# tviic2d6mddr register map
Vendor: Cypress Semiconductor; Series: tviic2d6mddr; File version: 1.0
CPU: CM7 r0p1, little endian, MPU, FPU, VTOR, 3 interrupt priority bits
Registers are 32-bit, read-write, reset 0x0 unless marked. A register's access mark holds for its fields unless they carry their own. Offsets are from the block's base; [hi:lo] are bit positions; lines under a group give offsets from that group; {n}, {i} and the like mark numbered series; 'fields as' and 'values as' point back to an identical list.

## VIDEOSS0 (part 4 of 18) — Video and Graphics Subsystem IP
Base 0x40A00000
0x80000 VIDEOIO group — Video I/O Core
  0x00 SUBIO group — Sub Interface
    0x00 VIDEOIOCFG group — Video I/O Core Configuration
      0x00 INTR_VIDEOIO0 — Interrupt status register 0
        [23:0] INTR_VIDEOIO0 — Interrupt status vector. A bit is set when the related event occurs or the corresponding bit of INTR_VIDEOIO0_SET is written. By writing 1 the corresponding bit is cleared. Bit 0 = ExtDst0_ShdLoad Bit 1 = ExtDst0_FrameComplete Bit 2 = ExtDst0_SeqComplete Bit 3 = ExtDst4_ShdLoad Bit 4 = ExtDst4_FrameComplete Bit 5 = ExtDst4_SeqComplete Bit 6 = ExtDst1_ShdLoad Bit 7 = ExtDst1_FrameComplete Bit 8 = ExtDst1_SeqComplete Bit 9 = ExtDst5_ShdLoad Bit 10 = ExtDst5_FrameComplete Bit 11 = ExtDst5_SeqComplete Bit 12 = Store4_ShdLoad Bit 13 = Store4_FrameComplete Bit 14 = Store4_SeqComplete Bit 15 = Histogram4_Valid Bit 16 = FrameDump_Error Bit 17 = FrameCap0_Sync_On Bit 18 = FrameCap0_Sync_Off Bit 19 = ItuIfc0_Error Bit 20 = GeneralPurpose0 Bit 21 = GeneralPurpose1 Bit 22 = GeneralPurpose2 Bit 23 = GeneralPurpose3
      0x04 INTR_VIDEOIO1 — Interrupt Status register 1
      0x08 INTR_VIDEOIO0_SET wo reset not defined — Interrupt set register 0
        [23:0] INTR_VIDEOIO0_SET — Interrupt set vector. Writing a 1 to this fields sets status in INTR_VIDEOIO0.
      0x0C INTR_VIDEOIO1_SET wo reset not defined — Interrupt set register 1
        [31:0] INTR_VIDEOIO1_SET — Interrupt set vector. Writing a 1 to this fields sets status in INTR_VIDEOIO1.
      0x10 INTR_VIDEOIO0_MASK — Interrupt mask register 0
        [23:0] INTR_VIDEOIO0_MASK — Interrupt mask vector. When a bit is set in this field, the related INTR_VIDEOIO0 status activates the interrupt signal.
      0x14 INTR_VIDEOIO1_MASK — Interrupt mask register 1
        [31:0] INTR_VIDEOIO1_MASK — Interrupt mask vector. When a bit is set in this field, the related INTR_VIDEOIO1 status activates the interrupt signal.
      0x18 INTR_VIDEOIO0_MASKED ro reset not defined — Interrupt masked register 0
        [23:0] INTR_VIDEOIO0_MASKED — Status vector INTR_VIDEOIO0 masked with INTR_VIDEOIO0_MASK.
      0x1C INTR_VIDEOIO1_MASKED ro reset not defined — Interrupt masked register 1
        [31:0] INTR_VIDEOIO1_MASKED — Status vector INTR_VIDEOIO1 masked with INTR_VIDEOIO1_MASK.
      0x20 INTR_VIDEOIO0_SAFETY — Interrupt Status register 0
        [23:0] INTR_VIDEOIO0_SAFETY — Interrupt status vector. A bit is set when the related event occurs or the corresponding bit of INTR_VIDEOIO0_SET is written. By writing 1 the corresponding bit is cleared. Bit mapping is same like in INTR_VIDEOIO0.
      0x24 INTR_VIDEOIO1_SAFETY — Interrupt Status register 1
        [31:0] INTR_VIDEOIO1_SAFETY — Interrupt status vector. A bit is set when the related event occurs or the corresponding bit of INTR_VIDEOIO0_SET is written. By writing 1 the corresponding bit is cleared. Bit mapping is same like in INTR_VIDEOIO1.
      0x28 INTR_VIDEOIO0_SAFETY_SET wo reset not defined — Interrupt set register 0
        [23:0] INTR_VIDEOIO0_SAFETY_SET — Interrupt set vector. Writing a 1 to this fields sets status in INTR_VIDEOIO0_SAFETY.
      0x2C INTR_VIDEOIO1_SAFETY_SET wo reset not defined — Interrupt set register 1
        [31:0] INTR_VIDEOIO1_SAFETY_SET — Interrupt set vector. Writing a 1 to this fields sets status in INTR_VIDEOIO1_SAFETY.
      0x30 INTR_VIDEOIO0_SAFETY_MASK — Interrupt mask register 0
        [23:0] INTR_VIDEOIO0_SAFETY_MASK — Interrupt mask vector. When a bit is set in this field, the related INTR_VIDEOIO0_SAFETY status activates the interrupt_safety signal.
      0x34 INTR_VIDEOIO1_SAFETY_MASK — Interrupt mask register 1
        [31:0] INTR_VIDEOIO1_SAFETY_MASK — Interrupt mask vector. When a bit is set in this field, the related INTR_VIDEOIO1_SAFETY status activates the interrupt_safety signal.
      0x38 INTR_VIDEOIO0_SAFETY_MASKED ro reset not defined — Interrupt masked register 0
        [23:0] INTR_VIDEOIO0_SAFETY_MASKED — Status vector INTR_VIDEOIO0_SAFETY masked with INTR_MASK_SAFETY0.
      0x3C INTR_VIDEOIO1_SAFETY_MASKED ro reset not defined — Interrupt masked register 1
        [31:0] INTR_VIDEOIO1_SAFETY_MASKED — Status vector INTR_VIDEOIO1_SAFETY masked with INTR_MASK_SAFETY1.
    0x400 FRAMEDUMP group — Frame Dump Unit
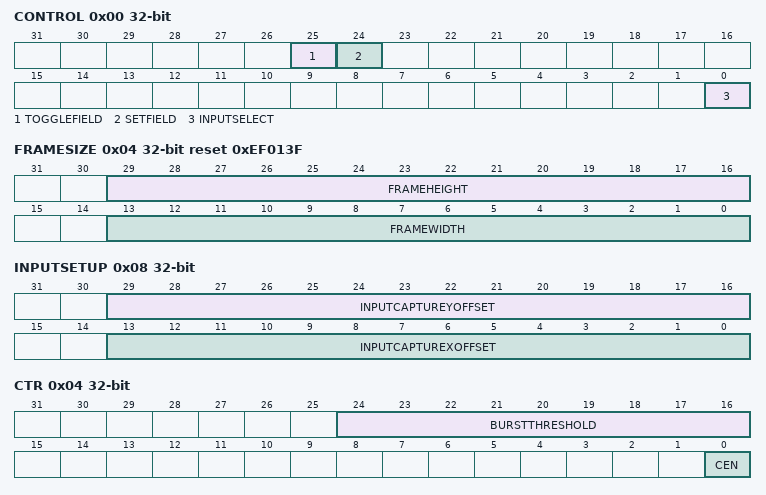
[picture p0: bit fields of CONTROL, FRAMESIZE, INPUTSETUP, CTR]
      0x00 CONTROL — Control settings.
        [25] TOGGLEFIELD — Enable toggling of the field property from frame to frame. Set to '1' to enable.
        [24] SETFIELD — The field property of the generated frame is set to this value. If field toggle is used, this is the start value.
        [0] INPUTSELECT — Index of display stream that is dumped.
      0x04 FRAMESIZE reset 0xEF013F — Dump window size.
        [29:16] FRAMEHEIGHT — Height of output frame of framedump, given minus one. Do not change during operation.
        [13:0] FRAMEWIDTH — Width of output frame of framedump, given minus one. Do not change during operation.
      0x08 INPUTSETUP — Dump window position.
        [29:16] INPUTCAPTUREYOFFSET — Y offset of capture area. Note that capture windows must not overlap the last row of the input frame. Do not change during operation.
        [13:0] INPUTCAPTUREXOFFSET — X offset of capture area. Note that capture windows must not overlap the last column of the input frame. Do not change during operation.
      0x0C ENABLE
        [0] DUMPEN — If this is set to 1, the framedump unit will continuously dump all input frames. If set to 0, DumpReq is the other option of triggering the dumping of an input frame.
      0x10 TRIGGER — Trigger bits.
        [0] DUMPREQ — Next frame is dumped when this field is set. It is reset by HW once dumping of frame data has started. It cannot be reset by SW.
      0x14 STATUS ro reset 0x1
        [0] DUMPIDLE — If read as '1', the framedump unit is currently not dumping any frames. If read as '0' the framedump unit is currently dumping frames.
    0x1000 CAPENG0 group — Capture Engine
      0x400 FRAMECAP group — Frame Capture Unit
        0x00 CAPTUREMODE — Capture mode configuration. FrameCap input mode configuration.
          [1:0] CAPTUREMODE — Selects a capture mode. Do not change during operation of FrameCap unit.
            0=ENHSVS_32BIT (Capture of 32-bit parallel or MIPI_CSI2 pixel input data with dedicated frame synchronization signals); 1=ITU656_10BIT (Capture of ITU656 10 bit data); 2=ITU656_8BIT (Capture of ITU656 8 bit data)
        0x04 CTR — FrameCap control register for starting the unit
          [24:16] BURSTTHRESHOLD — When setting a burst threshold larger 0, the generation of output pixels is initially locked. It is unlocked once the number of pixels captured into an internal FIFO is larger than the programmed value or when the last active pixel of an input frame has been received. Once unlocked it is locked again when the FIFO runs empty. This function can have a positive effect on memory access efficiency, depending on the system's Video RAM type.
          [0] CEN — CaptureEnable=1, enable bit for FrameCap unit. Capture starts with next frame sync signal. CaptureEnable=0, disable bit for FrameCap unit. Current frame is completed before FrameCap is stopped.
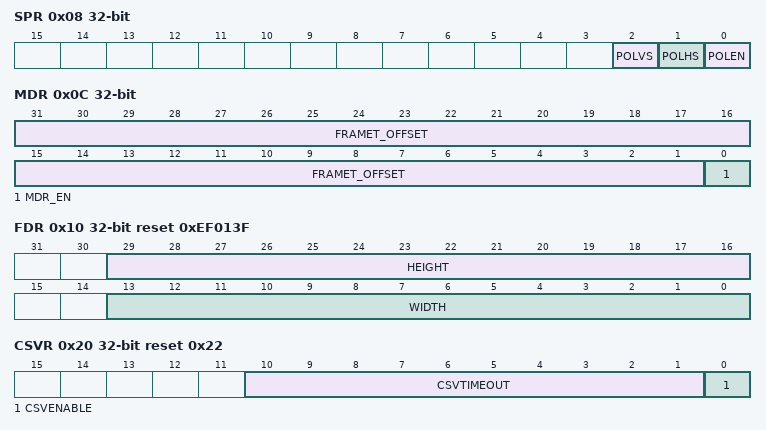
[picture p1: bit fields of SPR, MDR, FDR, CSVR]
        0x08 SPR — FrameCap sync signal polarity configuration.
          [2] POLVS — Change polarity of video signal vsync.
            0=LOWACT (Signal is active low (default).); 1=HIGHACT (Signal is active high.)
          [1] POLHS — Change polarity of video signal hsync.
            values as POLVS
          [0] POLEN — Change polarity of video signal de.
            0=HIGHACT (Signal is active high (default).); 1=LOWACT (Signal is active low.)
        0x0C MDR — FrameCap control register for starting the mode detection
          [31:1] FRAMET_OFFSET — Frame size tolerance which will not generate a mode detection size mismatch. Set an offset for frame time duration.
          [0] MDR_EN — Mdr_en=1, enable bit for FrameCap mode detection and pixel frame rate measurement for the captured frame. Make sure that MdSts0.MdrCmrDone is 1 before starting it again. Mdr_en=0, disable bit for FrameCap mode detection.
        0x10 FDR reset 0xEF013F — Frame dimension (progressive frame and field 0).
          [29:16] HEIGHT — Expected frame height of video frames and fields with id 0 (value is Height - 1). It could be configured after mode detection.
          [13:0] WIDTH — Expected frame width of video frame (value is Width - 1). It could be configured after mode detection.
        0x14 FDR1 reset 0xEF0000 — Frame dimension (field 1).
          [29:16] HEIGHT1 — Expected frame height of video fields with id 1 (value is Height - 1). It could be configured after mode detection.
        0x18 KDR — FrameCap kick delay configuration register
          [27:0] KICKDEL — Delay after receiving last active pixel in frame (in video clock cycles) until the kick pulse is generated. In any case the kick pulse is generated with first active pixel of next frame latest.
        0x1C SCR reset 0x2 — FrameCap Sync frame number configuration register
          [3:0] FUS — Number of consecutive frames captured until synchronization state is reached (value of 0 is not allowed). indicated by sts signal and register field Sts.SyncStat.
        0x20 CSVR reset 0x22 — Framecap control register for capture clock supervision
          [10:1] CSVTIMEOUT — setting a time limitation for waiting the recovery of capture clock. The value should be bigger than 11 or equal to 11, otherwise it reports fake clk_cap loss.
          [0] CSVENABLE — CsvEnable=1, start a capture clock supervision.
        0x24 STSCLR wo reset not defined — FrameCap status clear register. Clears the status bits of Sts register, Mdr_SizeChange and Csv_lost field.
          [0] STATUSCLEAR — Clears status bits of Sts register.
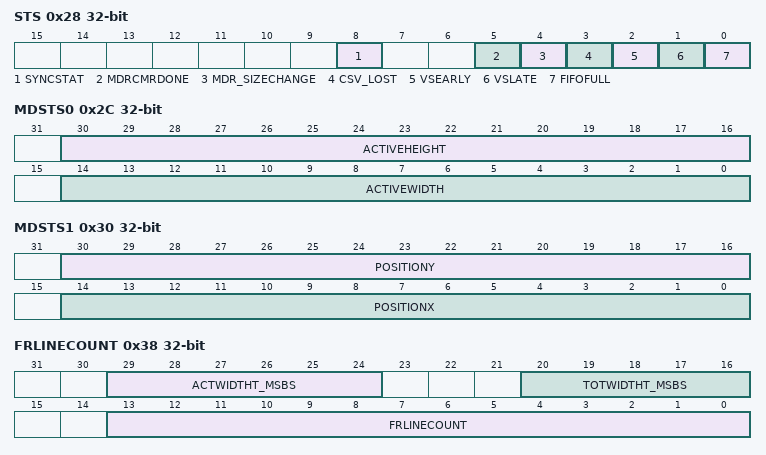
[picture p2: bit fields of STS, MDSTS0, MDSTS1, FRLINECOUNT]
        0x28 STS ro — FrameCap status register. Current status of the FrameCap module.
          [8] SYNCSTAT — Indicates the current state of synchronization (0 = out of sync, 1 = in sync). Note: A loss of the video stream cannot be detected using this field. Use the framegen status fields for this purpose.
          [5] MDRCMRDONE — MdrCmrDone=1 means that the mode detection is completed and pixel clock measurement is done. (bit locked when 1, clear by writing StatusClear field).
          [4] MDR_SIZECHANGE — Mdr_SizeChange=1, frame size of the video frame detected is not consistent. (bit locked when 1, clear by writing StatusClear field). If frame size change, the clock measurement fails.
          [3] CSV_LOST — Csv_Lost=1, capture clock is not available. Csv_Lost=0, capture clock is resumed.(bit locked when 1, cleared by writing StatusClear field).
          [2] VSEARLY — VSYNC is detected too early. The received frame is too small (bit locked when 1, cleared by writing StatusClear field).
          [1] VSLATE — VSYNC is detected too late. The received frame is too big (bit locked when 1, cleared by writing StatusClear field).
          [0] FIFOFULL — Write Access to the full coupling FIFO (bit locked when 1, cleared by writing StatusClear field).
        0x2C MDSTS0 ro — FrameCap mode detection status register for the active part of the video frames.(bit locked when MdrCmrDone=1).
          [30:16] ACTIVEHEIGHT — Frame height of active part of the video frame detected by the mode detection. The status can be read when MdrCmrDone=1.
          [14:0] ACTIVEWIDTH — Frame width of active part of the video frame detected by the mode detection. The status can be read when MdrCmrDone=1.
        0x30 MDSTS1 ro — FrameCap mode detection status register. The current (x,y) position of the capture stream (with respect to the output).
          [30:16] POSITIONY — the current Y position of the capture stream.
          [14:0] POSITIONX — the current X position of the capture stream.
        0x34 FRCNT ro — FrameCap frame counter register indicating the corresponding clk_axi cycles.
          [31:0] FRCOUNT — Shows frame counts of video input. It is updated every vsync (for debugging purposes only).
        0x38 FRLINECOUNT ro (reset mask 0x3F1F0000) — FrameCap line counter register.
          [29:24] ACTWIDTHT_MSBS — MSBs of CmSts1.ActWidthT. Bit locked when MdrCmrDone=1.
          [20:16] TOTWIDTHT_MSBS — MSBs of CmSts1.TotWidthT. Bit locked when MdrCmrDone=1.
          [13:0] FRLINECOUNT — Shows current line number of input timing. Incremented with leading edge of hsync signal, set to 0 with leading edge of vsync signal.
        0x3C CMSTS1 ro — clk_axi cycle number of a frame. (bit locked when MdrCmrDone=1).
          [29:0] TOTAL_TIME — clk_axi cycle number of a frame starting from vsync to another vsync.
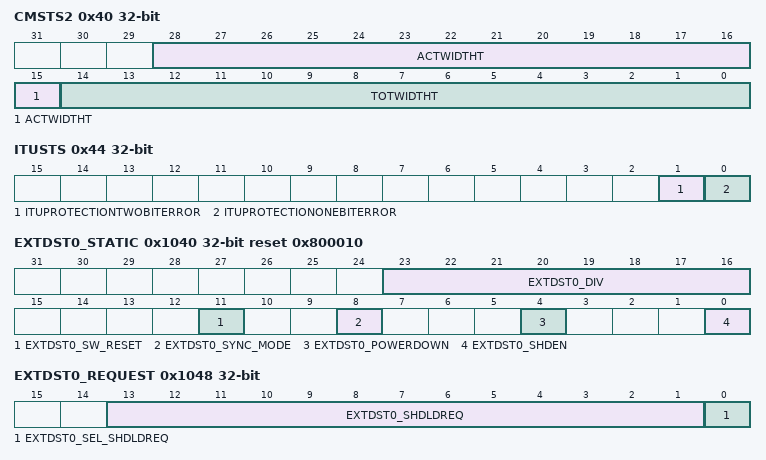
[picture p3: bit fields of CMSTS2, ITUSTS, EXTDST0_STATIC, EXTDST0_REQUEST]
        0x40 CMSTS2 ro — clk_axi cycle number of totwidth and actwidth of a frame. (bit locked when MdrCmrDone=1).
          [28:15] ACTWIDTHT — cycle number of the active part of a video frame line for calculating pixel frame rate. LSBs contained in this field, MSBs contained in FRLineCount.ActWidthT_MSBs.
          [14:0] TOTWIDTHT — cycle number of the total part of a video frame line for calculating pixel frame rate. LSBs contained in this field, MSBs contained in FRLineCount.TotWidthT_MSBs.
        0x44 ITUSTS — ITU error status register.
          [1] ITUPROTECTIONTWOBITERROR — Set if a two bit error in the reference code of the ITU capture input 0 is found. Two bit errors can only be detected, not corrected. Clear by writing a 1 to this field.
          [0] ITUPROTECTIONONEBITERROR — Set if a one bit error in the reference code of the ITU capture input 0 is found and corrected. Clear by writing a 1 to this field.
    0x10000 COMPENG group — Composition Engine
      0x00 COMPENGCFG group — Top-Level
        {0x0+4m} PALETTE[{m}] (m=0..1023) reset not defined — Shared Color Palette Memory.
          [23:0] PALETTEENTRY — Shared palette entry with 24-bit. Color format can be defined by Fetch configuration.
        0x1000 EXTDST0_SAFETYMASK reset 0x1FFFFF — Safety mask for extdst0
          [20:0] EXTDST0_SAFETYMASK — Each bit in this field describes whether the corresponding processing unit is allowed to be configured in a path leading to this endpoint (extdst0). 1 = allowed, 0 = prohibited.
        0x1004 EXTDST4_SAFETYMASK reset 0x1FFFFF — Safety mask for extdst4
          [20:0] EXTDST4_SAFETYMASK — Each bit in this field describes whether the corresponding processing unit is allowed to be configured in a path leading to this endpoint (extdst4). 1 = allowed, 0 = prohibited.
        0x1008 EXTDST1_SAFETYMASK reset 0x1FFFFF — Safety mask for extdst1
          [20:0] EXTDST1_SAFETYMASK — Each bit in this field describes whether the corresponding processing unit is allowed to be configured in a path leading to this endpoint (extdst1). 1 = allowed, 0 = prohibited.
        0x100C EXTDST5_SAFETYMASK reset 0x1FFFFF — Safety mask for extdst5
          [20:0] EXTDST5_SAFETYMASK — Each bit in this field describes whether the corresponding processing unit is allowed to be configured in a path leading to this endpoint (extdst5). 1 = allowed, 0 = prohibited.
        0x1010 STORE4_SAFETYMASK reset 0x1FFFFF — Safety mask for store4
          [20:0] STORE4_SAFETYMASK — Each bit in this field describes whether the corresponding processing unit is allowed to be configured in a path leading to this endpoint (store4). 1 = allowed, 0 = prohibited.
        0x1020 CONSTFRAME0_STATUS ro reset not defined — Status information for pixel engine configuration of constframe0
          [18:16] CONSTFRAME0_SEL — Status of the connection of the constframe0 module
            1=EXTDST0 (constframe0 module is used from extdst0 processing path); 2=EXTDST4 (constframe0 module is used from extdst4 processing path); 3=EXTDST1 (constframe0 module is used from extdst1 processing path); 4=EXTDST5 (constframe0 module is used from extdst5 processing path); 5=STORE4 (constframe0 module is used from store4 processing path); 0=DISABLE (constframe0 module is not used)
        0x1040 EXTDST0_STATIC reset 0x800010 — Static pixel engine configuration for extdst0
          [23:16] EXTDST0_DIV
          [11] EXTDST0_SW_RESET — Software reset for extdst0 synchronizer, for debug purposes only
            0=OPERATION (Normal Operation); 1=SWRESET (Software Reset)
          [8] EXTDST0_SYNC_MODE — Synchronization mode for extdst0 pipeline endpoint synchronizer
            0=SINGLE (Reconfig pipeline after explicit trigger); 1=AUTO (Reconfig pipeline after every kick when idle)
          [4] EXTDST0_POWERDOWN — Set this to 1 to activate powerdown or to 0 to deactivate powerdown for the extdst0 endpoint.
          [0] EXTDST0_SHDEN — Enables shadowing of all RWS type registers (0=write_through, 1=shadowed) for pixelbus configuration of pipeline with endpoint extdst0.
        0x1044 EXTDST0_DYNAMIC reset 0x17 — Dynamic pixel engine configuration for extdst0
          [4:0] EXTDST0_SRC_SEL — Selection of the source for the src input of the extdst0 module
            0=DISABLE (Unit extdst0 input port src is disabled); 1=CONSTFRAME0 (Unit extdst0 input port src is connected to output of unit constframe0); 20=GPSCALER4 (Unit extdst0 input port src is connected to output of unit gpscaler4); 9=EXTSRC4 (Unit extdst0 input port src is connected to output of unit extsrc4); {v}=LAYERBLEND{v-21} (Unit extdst0 input port src is connected to output of unit layerblend{v-21}) (v=22..26)
        0x1048 EXTDST0_REQUEST — ShadowLoadRequest register for endpoint extdst0
          [13:1] EXTDST0_SHDLDREQ — Vector of shadow load request flag of all sources for destination extdst0. Setting a bit has no effect if the source is currently in a different pipeline than the one of destination extdst0.
          [0] EXTDST0_SEL_SHDLDREQ — Shadow load request flag for destination extdst0.
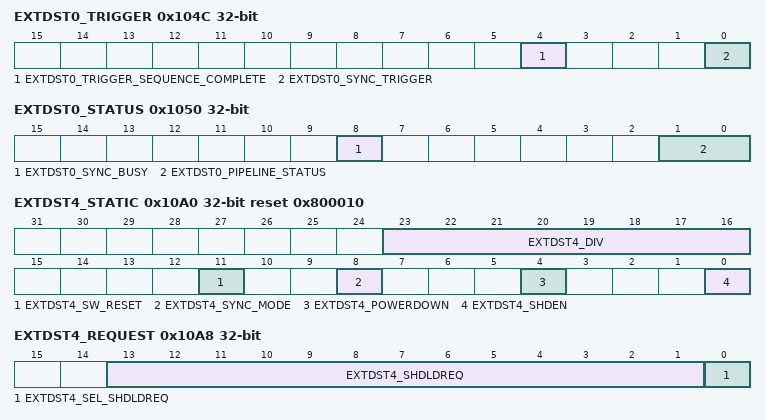
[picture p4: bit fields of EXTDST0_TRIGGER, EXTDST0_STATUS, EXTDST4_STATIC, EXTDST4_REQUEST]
        0x104C EXTDST0_TRIGGER wo reset not defined — Trigger bits for pixel engine configuration of extdst0
          [4] EXTDST0_TRIGGER_SEQUENCE_COMPLETE — By writing a '1' to this register field, you can trigger the extdst0 sequence complete interrupt that will occur as soon as the pipeline with the endpoint extdst0 is empty. This interrupt will also occur if the pipeline is already empty when this field is written. The interrupt will not occur if this field is not written. The interrupt will occur exactly as often as this field is written, assuming that this field is not written again until the interrupt has occured after a previous trigger.
          [0] EXTDST0_SYNC_TRIGGER — Writing a '1' to this field triggers reconfiguration of the pipeline with endpoint extdst0
        0x1050 EXTDST0_STATUS ro — Status information for pixel engine configuration of extdst0
          [8] EXTDST0_SYNC_BUSY — Synchronization busy status of extdst0 endpoint
            0=IDLE (extdst0 synchronizer is idle); 1=BUSY (extdst0 synchronizer is busy)
          [1:0] EXTDST0_PIPELINE_STATUS — Status of pipeline with endpoint extdst0
            0=EMPTY (Pipeline with endpoint extdst0 is empty); 1=RUNNING (Pipeline with endpoint extdst0 is currently processing one operation); 2=RUNNING_RETRIGGERED (Pipeline with endpoint extdst0 is currently processing one operation with a second one already kicked to be processed afterwards); 3=RSVD (N/A)
        0x1080 CONSTFRAME4_STATUS ro reset not defined — Status information for pixel engine configuration of constframe4
          [18:16] CONSTFRAME4_SEL — Status of the connection of the constframe4 module
            1=EXTDST0 (constframe4 module is used from extdst0 processing path); 2=EXTDST4 (constframe4 module is used from extdst4 processing path); 3=EXTDST1 (constframe4 module is used from extdst1 processing path); 4=EXTDST5 (constframe4 module is used from extdst5 processing path); 5=STORE4 (constframe4 module is used from store4 processing path); 0=DISABLE (constframe4 module is not used)
        0x10A0 EXTDST4_STATIC reset 0x800010 — Static pixel engine configuration for extdst4
          [23:16] EXTDST4_DIV
          [11] EXTDST4_SW_RESET — Software reset for extdst4 synchronizer, for debug purposes only
            0=OPERATION (Normal Operation); 1=SWRESET (Software Reset)
          [8] EXTDST4_SYNC_MODE — Synchronization mode for extdst4 pipeline endpoint synchronizer
            values as VIDEOIO.SUBIO.COMPENG.COMPENGCFG.EXTDST0_STATIC.EXTDST0_SYNC_MODE
          [4] EXTDST4_POWERDOWN — Set this to 1 to activate powerdown or to 0 to deactivate powerdown for the extdst4 endpoint.
          [0] EXTDST4_SHDEN — Enables shadowing of all RWS type registers (0=write_through, 1=shadowed) for pixelbus configuration of pipeline with endpoint extdst4.
        0x10A4 EXTDST4_DYNAMIC — Dynamic pixel engine configuration for extdst4
          [4:0] EXTDST4_SRC_SEL — Selection of the source for the src input of the extdst4 module
            0=DISABLE (Unit extdst4 input port src is disabled); 3=CONSTFRAME4 (Unit extdst4 input port src is connected to output of unit constframe4); 20=GPSCALER4 (Unit extdst4 input port src is connected to output of unit gpscaler4); 9=EXTSRC4 (Unit extdst4 input port src is connected to output of unit extsrc4); {v}=LAYERBLEND{v-21} (Unit extdst4 input port src is connected to output of unit layerblend{v-21}) (v=22..26)
        0x10A8 EXTDST4_REQUEST — ShadowLoadRequest register for endpoint extdst4
          [13:1] EXTDST4_SHDLDREQ — Vector of shadow load request flag of all sources for destination extdst4. Setting a bit has no effect if the source is currently in a different pipeline than the one of destination extdst4.
          [0] EXTDST4_SEL_SHDLDREQ — Shadow load request flag for destination extdst4.
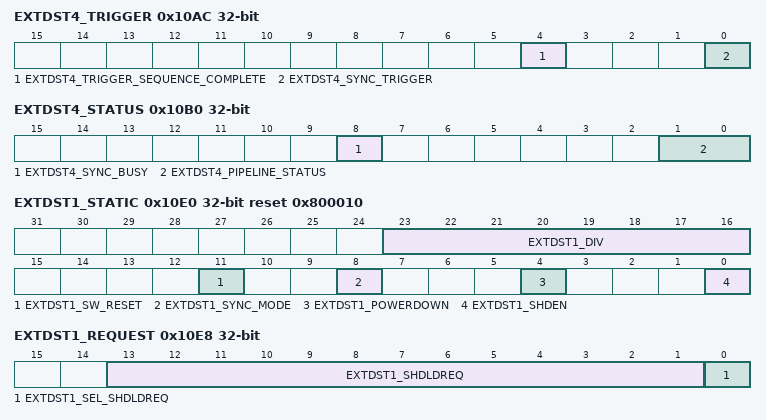
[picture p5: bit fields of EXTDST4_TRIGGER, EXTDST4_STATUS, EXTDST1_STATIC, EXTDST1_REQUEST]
        0x10AC EXTDST4_TRIGGER wo reset not defined — Trigger bits for pixel engine configuration of extdst4
          [4] EXTDST4_TRIGGER_SEQUENCE_COMPLETE — By writing a '1' to this register field, you can trigger the extdst4 sequence complete interrupt that will occur as soon as the pipeline with the endpoint extdst4 is empty. This interrupt will also occur if the pipeline is already empty when this field is written. The interrupt will not occur if this field is not written. The interrupt will occur exactly as often as this field is written, assuming that this field is not written again until the interrupt has occured after a previous trigger.
          [0] EXTDST4_SYNC_TRIGGER — Writing a '1' to this field triggers reconfiguration of the pipeline with endpoint extdst4
        0x10B0 EXTDST4_STATUS ro — Status information for pixel engine configuration of extdst4
          [8] EXTDST4_SYNC_BUSY — Synchronization busy status of extdst4 endpoint
            0=IDLE (extdst4 synchronizer is idle); 1=BUSY (extdst4 synchronizer is busy)
          [1:0] EXTDST4_PIPELINE_STATUS — Status of pipeline with endpoint extdst4
            0=EMPTY (Pipeline with endpoint extdst4 is empty); 1=RUNNING (Pipeline with endpoint extdst4 is currently processing one operation); 2=RUNNING_RETRIGGERED (Pipeline with endpoint extdst4 is currently processing one operation with a second one already kicked to be processed afterwards); 3=RSVD (N/A)
        0x10C0 CONSTFRAME1_STATUS ro reset not defined — Status information for pixel engine configuration of constframe1
          [18:16] CONSTFRAME1_SEL — Status of the connection of the constframe1 module
            1=EXTDST0 (constframe1 module is used from extdst0 processing path); 2=EXTDST4 (constframe1 module is used from extdst4 processing path); 3=EXTDST1 (constframe1 module is used from extdst1 processing path); 4=EXTDST5 (constframe1 module is used from extdst5 processing path); 5=STORE4 (constframe1 module is used from store4 processing path); 0=DISABLE (constframe1 module is not used)
        0x10E0 EXTDST1_STATIC reset 0x800010 — Static pixel engine configuration for extdst1
          [23:16] EXTDST1_DIV
          [11] EXTDST1_SW_RESET — Software reset for extdst1 synchronizer, for debug purposes only
            0=OPERATION (Normal Operation); 1=SWRESET (Software Reset)
          [8] EXTDST1_SYNC_MODE — Synchronization mode for extdst1 pipeline endpoint synchronizer
            values as VIDEOIO.SUBIO.COMPENG.COMPENGCFG.EXTDST0_STATIC.EXTDST0_SYNC_MODE
          [4] EXTDST1_POWERDOWN — Set this to 1 to activate powerdown or to 0 to deactivate powerdown for the extdst1 endpoint.
          [0] EXTDST1_SHDEN — Enables shadowing of all RWS type registers (0=write_through, 1=shadowed) for pixelbus configuration of pipeline with endpoint extdst1.
        0x10E4 EXTDST1_DYNAMIC reset 0x18 — Dynamic pixel engine configuration for extdst1
          [4:0] EXTDST1_SRC_SEL — Selection of the source for the src input of the extdst1 module
            0=DISABLE (Unit extdst1 input port src is disabled); 5=CONSTFRAME1 (Unit extdst1 input port src is connected to output of unit constframe1); 20=GPSCALER4 (Unit extdst1 input port src is connected to output of unit gpscaler4); 9=EXTSRC4 (Unit extdst1 input port src is connected to output of unit extsrc4); {v}=LAYERBLEND{v-21} (Unit extdst1 input port src is connected to output of unit layerblend{v-21}) (v=22..26)
        0x10E8 EXTDST1_REQUEST — ShadowLoadRequest register for endpoint extdst1
          [13:1] EXTDST1_SHDLDREQ — Vector of shadow load request flag of all sources for destination extdst1. Setting a bit has no effect if the source is currently in a different pipeline than the one of destination extdst1.
          [0] EXTDST1_SEL_SHDLDREQ — Shadow load request flag for destination extdst1.
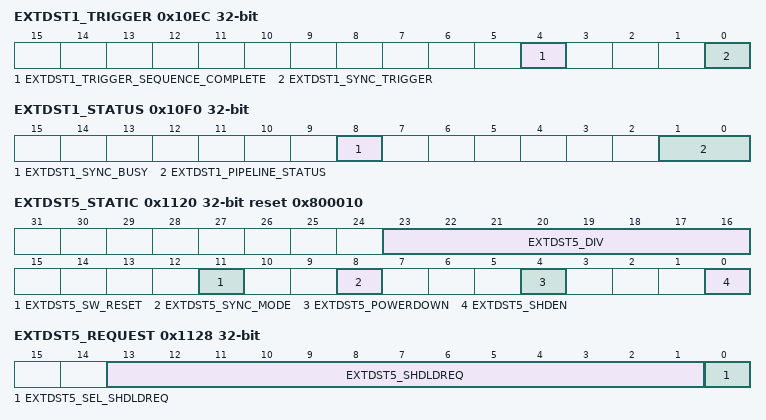
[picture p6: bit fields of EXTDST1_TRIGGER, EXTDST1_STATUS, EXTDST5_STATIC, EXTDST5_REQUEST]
        0x10EC EXTDST1_TRIGGER wo reset not defined — Trigger bits for pixel engine configuration of extdst1
          [4] EXTDST1_TRIGGER_SEQUENCE_COMPLETE — By writing a '1' to this register field, you can trigger the extdst1 sequence complete interrupt that will occur as soon as the pipeline with the endpoint extdst1 is empty. This interrupt will also occur if the pipeline is already empty when this field is written. The interrupt will not occur if this field is not written. The interrupt will occur exactly as often as this field is written, assuming that this field is not written again until the interrupt has occured after a previous trigger.
          [0] EXTDST1_SYNC_TRIGGER — Writing a '1' to this field triggers reconfiguration of the pipeline with endpoint extdst1
        0x10F0 EXTDST1_STATUS ro — Status information for pixel engine configuration of extdst1
          [8] EXTDST1_SYNC_BUSY — Synchronization busy status of extdst1 endpoint
            0=IDLE (extdst1 synchronizer is idle); 1=BUSY (extdst1 synchronizer is busy)
          [1:0] EXTDST1_PIPELINE_STATUS — Status of pipeline with endpoint extdst1
            0=EMPTY (Pipeline with endpoint extdst1 is empty); 1=RUNNING (Pipeline with endpoint extdst1 is currently processing one operation); 2=RUNNING_RETRIGGERED (Pipeline with endpoint extdst1 is currently processing one operation with a second one already kicked to be processed afterwards); 3=RSVD (N/A)
        0x1100 CONSTFRAME5_STATUS ro reset not defined — Status information for pixel engine configuration of constframe5
          [18:16] CONSTFRAME5_SEL — Status of the connection of the constframe5 module
            1=EXTDST0 (constframe5 module is used from extdst0 processing path); 2=EXTDST4 (constframe5 module is used from extdst4 processing path); 3=EXTDST1 (constframe5 module is used from extdst1 processing path); 4=EXTDST5 (constframe5 module is used from extdst5 processing path); 5=STORE4 (constframe5 module is used from store4 processing path); 0=DISABLE (constframe5 module is not used)
        0x1120 EXTDST5_STATIC reset 0x800010 — Static pixel engine configuration for extdst5
          [23:16] EXTDST5_DIV
          [11] EXTDST5_SW_RESET — Software reset for extdst5 synchronizer, for debug purposes only
            0=OPERATION (Normal Operation); 1=SWRESET (Software Reset)
          [8] EXTDST5_SYNC_MODE — Synchronization mode for extdst5 pipeline endpoint synchronizer
            values as VIDEOIO.SUBIO.COMPENG.COMPENGCFG.EXTDST0_STATIC.EXTDST0_SYNC_MODE
          [4] EXTDST5_POWERDOWN — Set this to 1 to activate powerdown or to 0 to deactivate powerdown for the extdst5 endpoint.
          [0] EXTDST5_SHDEN — Enables shadowing of all RWS type registers (0=write_through, 1=shadowed) for pixelbus configuration of pipeline with endpoint extdst5.
        0x1124 EXTDST5_DYNAMIC — Dynamic pixel engine configuration for extdst5
          [4:0] EXTDST5_SRC_SEL — Selection of the source for the src input of the extdst5 module
            0=DISABLE (Unit extdst5 input port src is disabled); 7=CONSTFRAME5 (Unit extdst5 input port src is connected to output of unit constframe5); 20=GPSCALER4 (Unit extdst5 input port src is connected to output of unit gpscaler4); 9=EXTSRC4 (Unit extdst5 input port src is connected to output of unit extsrc4); {v}=LAYERBLEND{v-21} (Unit extdst5 input port src is connected to output of unit layerblend{v-21}) (v=22..26)
        0x1128 EXTDST5_REQUEST — ShadowLoadRequest register for endpoint extdst5
          [13:1] EXTDST5_SHDLDREQ — Vector of shadow load request flag of all sources for destination extdst5. Setting a bit has no effect if the source is currently in a different pipeline than the one of destination extdst5.
          [0] EXTDST5_SEL_SHDLDREQ — Shadow load request flag for destination extdst5.
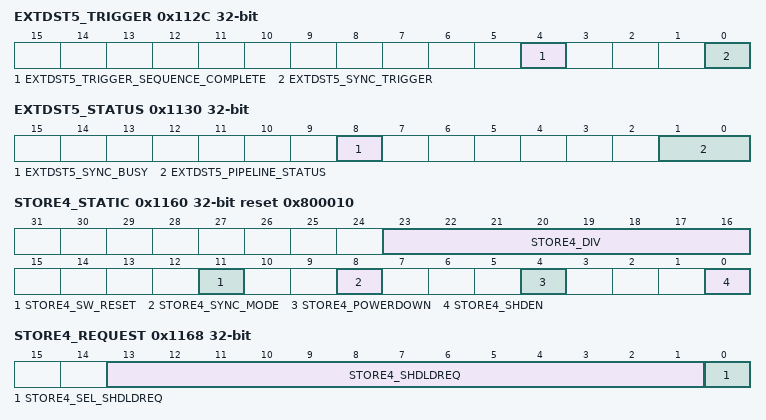
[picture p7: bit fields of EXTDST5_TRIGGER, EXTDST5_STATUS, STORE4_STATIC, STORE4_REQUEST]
        0x112C EXTDST5_TRIGGER wo reset not defined — Trigger bits for pixel engine configuration of extdst5
          [4] EXTDST5_TRIGGER_SEQUENCE_COMPLETE — By writing a '1' to this register field, you can trigger the extdst5 sequence complete interrupt that will occur as soon as the pipeline with the endpoint extdst5 is empty. This interrupt will also occur if the pipeline is already empty when this field is written. The interrupt will not occur if this field is not written. The interrupt will occur exactly as often as this field is written, assuming that this field is not written again until the interrupt has occured after a previous trigger.
          [0] EXTDST5_SYNC_TRIGGER — Writing a '1' to this field triggers reconfiguration of the pipeline with endpoint extdst5
        0x1130 EXTDST5_STATUS ro — Status information for pixel engine configuration of extdst5
          [8] EXTDST5_SYNC_BUSY — Synchronization busy status of extdst5 endpoint
            0=IDLE (extdst5 synchronizer is idle); 1=BUSY (extdst5 synchronizer is busy)
          [1:0] EXTDST5_PIPELINE_STATUS — Status of pipeline with endpoint extdst5
            0=EMPTY (Pipeline with endpoint extdst5 is empty); 1=RUNNING (Pipeline with endpoint extdst5 is currently processing one operation); 2=RUNNING_RETRIGGERED (Pipeline with endpoint extdst5 is currently processing one operation with a second one already kicked to be processed afterwards); 3=RSVD (N/A)
        0x1140 EXTSRC4_STATUS ro reset not defined — Status information for pixel engine configuration of extsrc4
          [18:16] EXTSRC4_SEL — Status of the connection of the extsrc4 module
            1=EXTDST0 (extsrc4 module is used from extdst0 processing path); 2=EXTDST4 (extsrc4 module is used from extdst4 processing path); 3=EXTDST1 (extsrc4 module is used from extdst1 processing path); 4=EXTDST5 (extsrc4 module is used from extdst5 processing path); 5=STORE4 (extsrc4 module is used from store4 processing path); 0=DISABLE (extsrc4 module is not used)
        0x1160 STORE4_STATIC reset 0x800010 — Static pixel engine configuration for store4
          [23:16] STORE4_DIV
          [11] STORE4_SW_RESET — Software reset for store4 synchronizer, for debug purposes only
            0=OPERATION (Normal Operation); 1=SWRESET (Software Reset)
          [8] STORE4_SYNC_MODE — Synchronization mode for store4 pipeline endpoint synchronizer
            values as VIDEOIO.SUBIO.COMPENG.COMPENGCFG.EXTDST0_STATIC.EXTDST0_SYNC_MODE
          [4] STORE4_POWERDOWN — Set this to 1 to activate powerdown or to 0 to deactivate powerdown for the store4 endpoint.
          [0] STORE4_SHDEN — Enables shadowing of all RWS type registers (0=write_through, 1=shadowed) for pixelbus configuration of pipeline with endpoint store4.
        0x1164 STORE4_DYNAMIC reset 0x9 — Dynamic pixel engine configuration for store4
          [4:0] STORE4_SRC_SEL — Selection of the source for the src input of the store4 module
            0=DISABLE (Unit store4 input port src is disabled); 27=EXTSRC8 (Unit store4 input port src is connected to output of unit extsrc8); 20=GPSCALER4 (Unit store4 input port src is connected to output of unit gpscaler4); 9=EXTSRC4 (Unit store4 input port src is connected to output of unit extsrc4); 19=MATRIX4 (Unit store4 input port src is connected to output of unit matrix4)
        0x1168 STORE4_REQUEST — ShadowLoadRequest register for endpoint store4
          [13:1] STORE4_SHDLDREQ — Vector of shadow load request flag of all sources for destination store4. Setting a bit has no effect if the source is currently in a different pipeline than the one of destination store4.
          [0] STORE4_SEL_SHDLDREQ — Shadow load request flag for destination store4.
